AUTOSAR XML (schema 4-2-2)
package /STELLANTIS/EPT/ASWCs
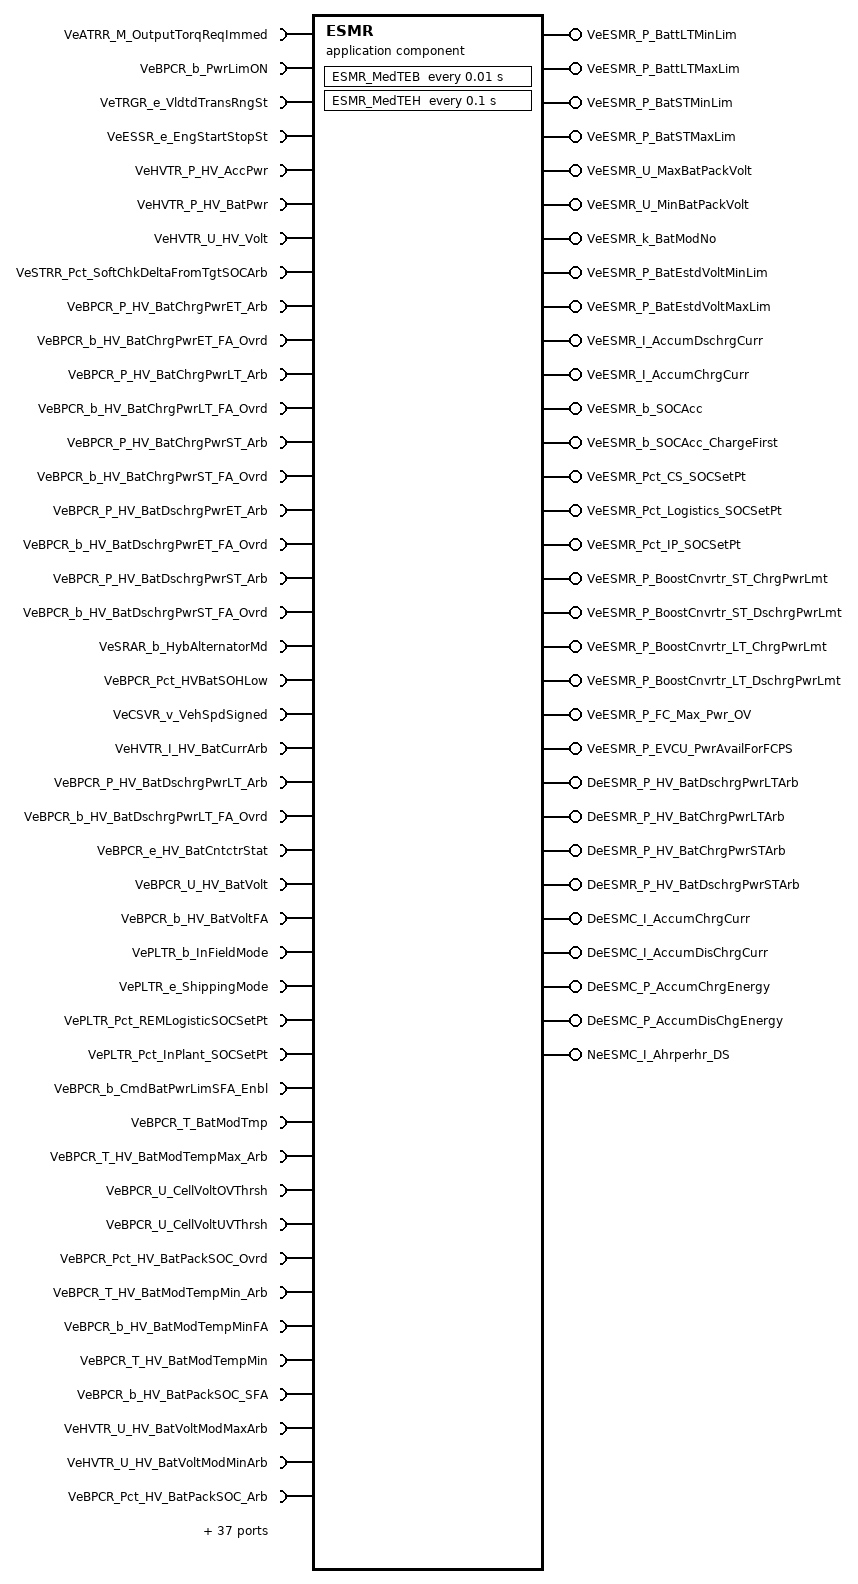
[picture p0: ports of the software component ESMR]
  application sw component type ESMR
    71 x require port:
      VeATRR_M_OutputTorqReqImmed: nonqueued-receiver-com-spec{data-element=Value, init-value=0}, required-interface=VeATRR_M_OutputTorqReqImmed
      VeBPCR_b_PwrLimON: nonqueued-receiver-com-spec{data-element=Value, init-value=0}, required-interface=VeBPCR_b_PwrLimON
      VeTRGR_e_VldtdTransRngSt: nonqueued-receiver-com-spec{data-element=Value, init-value=CeTRGR_e_NoSelectionAvailable}, required-interface=VeTRGR_e_VldtdTransRngSt
      VeESSR_e_EngStartStopSt: nonqueued-receiver-com-spec{data-element=Value, init-value=CeESSR_e_EngOff}, required-interface=VeESSR_e_EngStartStopSt
      VeHVTR_P_HV_AccPwr: nonqueued-receiver-com-spec{data-element=Value, init-value=0}, required-interface=VeHVTR_P_HV_AccPwr
      VeHVTR_P_HV_BatPwr: nonqueued-receiver-com-spec{data-element=Value, init-value=0}, required-interface=VeHVTR_P_HV_BatPwr
      VeHVTR_U_HV_Volt: nonqueued-receiver-com-spec{data-element=Value, init-value=0}, required-interface=VeHVTR_U_HV_Volt
      VeSTRR_Pct_SoftChkDeltaFromTgtSOCArb: nonqueued-receiver-com-spec{data-element=Value, init-value=0}, required-interface=VeSTRR_Pct_SoftChkDeltaFromTgtSOCArb
      VeBPCR_P_HV_BatChrgPwrET_Arb: nonqueued-receiver-com-spec{data-element=Value, init-value=0}, required-interface=VeBPCR_P_HV_BatChrgPwrET_Arb
      VeBPCR_b_HV_BatChrgPwrET_FA_Ovrd: nonqueued-receiver-com-spec{data-element=Value, init-value=0}, required-interface=VeBPCR_b_HV_BatChrgPwrET_FA_Ovrd
      VeBPCR_P_HV_BatChrgPwrLT_Arb: nonqueued-receiver-com-spec{data-element=Value, init-value=0}, required-interface=VeBPCR_P_HV_BatChrgPwrLT_Arb
      VeBPCR_b_HV_BatChrgPwrLT_FA_Ovrd: nonqueued-receiver-com-spec{data-element=Value, init-value=0}, required-interface=VeBPCR_b_HV_BatChrgPwrLT_FA_Ovrd
      VeBPCR_P_HV_BatChrgPwrST_Arb: nonqueued-receiver-com-spec{data-element=Value, init-value=0}, required-interface=VeBPCR_P_HV_BatChrgPwrST_Arb
      VeBPCR_b_HV_BatChrgPwrST_FA_Ovrd: nonqueued-receiver-com-spec{data-element=Value, init-value=0}, required-interface=VeBPCR_b_HV_BatChrgPwrST_FA_Ovrd
      VeBPCR_P_HV_BatDschrgPwrET_Arb: nonqueued-receiver-com-spec{data-element=Value, init-value=0}, required-interface=VeBPCR_P_HV_BatDschrgPwrET_Arb
      VeBPCR_b_HV_BatDschrgPwrET_FA_Ovrd: nonqueued-receiver-com-spec{data-element=Value, init-value=0}, required-interface=VeBPCR_b_HV_BatDschrgPwrET_FA_Ovrd
      VeBPCR_P_HV_BatDschrgPwrST_Arb: nonqueued-receiver-com-spec{data-element=Value, init-value=0}, required-interface=VeBPCR_P_HV_BatDschrgPwrST_Arb
      VeBPCR_b_HV_BatDschrgPwrST_FA_Ovrd: nonqueued-receiver-com-spec{data-element=Value, init-value=0}, required-interface=VeBPCR_b_HV_BatDschrgPwrST_FA_Ovrd
      VeSRAR_b_HybAlternatorMd: nonqueued-receiver-com-spec{data-element=Value, init-value=0}, required-interface=VeSRAR_b_HybAlternatorMd
      VeBPCR_Pct_HVBatSOHLow: nonqueued-receiver-com-spec{data-element=Value, init-value=0}, required-interface=VeBPCR_Pct_HVBatSOHLow
      VeCSVR_v_VehSpdSigned: nonqueued-receiver-com-spec{data-element=Value, init-value=0}, required-interface=VeCSVR_v_VehSpdSigned
      VeHVTR_I_HV_BatCurrArb: nonqueued-receiver-com-spec{data-element=Value, init-value=0}, required-interface=VeHVTR_I_HV_BatCurrArb
      VeBPCR_P_HV_BatDschrgPwrLT_Arb: nonqueued-receiver-com-spec{data-element=Value, init-value=0}, required-interface=VeBPCR_P_HV_BatDschrgPwrLT_Arb
      VeBPCR_b_HV_BatDschrgPwrLT_FA_Ovrd: nonqueued-receiver-com-spec{data-element=Value, init-value=0}, required-interface=VeBPCR_b_HV_BatDschrgPwrLT_FA_Ovrd
      VeBPCR_e_HV_BatCntctrStat: nonqueued-receiver-com-spec{data-element=Value, init-value=CeHVTR_e_Open}, required-interface=VeBPCR_e_HV_BatCntctrStat
      VeBPCR_U_HV_BatVolt: nonqueued-receiver-com-spec{data-element=Value, init-value=0}, required-interface=VeBPCR_U_HV_BatVolt
      VeBPCR_b_HV_BatVoltFA: nonqueued-receiver-com-spec{data-element=Value, init-value=0}, required-interface=VeBPCR_b_HV_BatVoltFA
      VePLTR_b_InFieldMode: nonqueued-receiver-com-spec{data-element=Value, init-value=0}, required-interface=VePLTR_b_InFieldMode
      VePLTR_e_ShippingMode: nonqueued-receiver-com-spec{data-element=Value, init-value=CePLTR_e_ShipingMode_CUST_MD}, required-interface=VePLTR_e_ShippingMode
      VePLTR_Pct_REMLogisticSOCSetPt: nonqueued-receiver-com-spec{data-element=Value, init-value=0}, required-interface=VePLTR_Pct_REMLogisticSOCSetPt
      VePLTR_Pct_InPlant_SOCSetPt: nonqueued-receiver-com-spec{data-element=Value, init-value=0}, required-interface=VePLTR_Pct_InPlant_SOCSetPt
      VeBPCR_b_CmdBatPwrLimSFA_Enbl: nonqueued-receiver-com-spec{data-element=Value, init-value=0}, required-interface=VeBPCR_b_CmdBatPwrLimSFA_Enbl
      VeBPCR_T_BatModTmp: nonqueued-receiver-com-spec{data-element=Value, init-value=0}, required-interface=VeBPCR_T_BatModTmp
      VeBPCR_T_HV_BatModTempMax_Arb: nonqueued-receiver-com-spec{data-element=Value, init-value=0}, required-interface=VeBPCR_T_HV_BatModTempMax_Arb
      VeBPCR_U_CellVoltOVThrsh: nonqueued-receiver-com-spec{data-element=Value, init-value=0}, required-interface=VeBPCR_U_CellVoltOVThrsh
      VeBPCR_U_CellVoltUVThrsh: nonqueued-receiver-com-spec{data-element=Value, init-value=0}, required-interface=VeBPCR_U_CellVoltUVThrsh
      VeBPCR_Pct_HV_BatPackSOC_Ovrd: nonqueued-receiver-com-spec{data-element=Value, init-value=0}, required-interface=VeBPCR_Pct_HV_BatPackSOC_Ovrd
      VeBPCR_T_HV_BatModTempMin_Arb: nonqueued-receiver-com-spec{data-element=Value, init-value=0}, required-interface=VeBPCR_T_HV_BatModTempMin_Arb
      VeBPCR_b_HV_BatModTempMinFA: nonqueued-receiver-com-spec{data-element=Value, init-value=0}, required-interface=VeBPCR_b_HV_BatModTempMinFA
      VeBPCR_T_HV_BatModTempMin: nonqueued-receiver-com-spec{data-element=Value, init-value=0}, required-interface=VeBPCR_T_HV_BatModTempMin
      VeBPCR_b_HV_BatPackSOC_SFA: nonqueued-receiver-com-spec{data-element=Value, init-value=0}, required-interface=VeBPCR_b_HV_BatPackSOC_SFA
      VeHVTR_U_HV_BatVoltModMaxArb: nonqueued-receiver-com-spec{data-element=Value, init-value=0}, required-interface=VeHVTR_U_HV_BatVoltModMaxArb
      VeHVTR_U_HV_BatVoltModMinArb: nonqueued-receiver-com-spec{data-element=Value, init-value=0}, required-interface=VeHVTR_U_HV_BatVoltModMinArb
      VeBPCR_Pct_HV_BatPackSOC_Arb: nonqueued-receiver-com-spec{data-element=Value, init-value=0}, required-interface=VeBPCR_Pct_HV_BatPackSOC_Arb
      VePLTR_b_InPlantAllowCharge: nonqueued-receiver-com-spec{data-element=Value, init-value=0}, required-interface=VePLTR_b_InPlantAllowCharge
      VeFCPR_U_FCPS_Volt: nonqueued-receiver-com-spec{data-element=Value, init-value=0}, required-interface=VeFCPR_U_FCPS_Volt
      VeFCPR_b_FCPS_Volt_FA: nonqueued-receiver-com-spec{data-element=Value, init-value=0}, required-interface=VeFCPR_b_FCPS_Volt_FA
      VeFCPR_U_FCPS_UpperVoltLIM: nonqueued-receiver-com-spec{data-element=Value, init-value=0}, required-interface=VeFCPR_U_FCPS_UpperVoltLIM
      VeFCPR_b_FCPS_UpperVoltLIM_FA: nonqueued-receiver-com-spec{data-element=Value, init-value=0}, required-interface=VeFCPR_b_FCPS_UpperVoltLIM_FA
      VeFCPR_U_FCPS_LowerVoltLIM: nonqueued-receiver-com-spec{data-element=Value, init-value=0}, required-interface=VeFCPR_U_FCPS_LowerVoltLIM
      VeFCPR_b_FCPS_LowerVoltLIM_FA: nonqueued-receiver-com-spec{data-element=Value, init-value=0}, required-interface=VeFCPR_b_FCPS_LowerVoltLIM_FA
      VeFCPR_P_FCPS_ShoTiDchaPwrLim: nonqueued-receiver-com-spec{data-element=Value, init-value=0}, required-interface=VeFCPR_P_FCPS_ShoTiDchaPwrLim
      VeFCPR_P_FCPS_LongTiDchaPwrLim: nonqueued-receiver-com-spec{data-element=Value, init-value=0}, required-interface=VeFCPR_P_FCPS_LongTiDchaPwrLim
      VeFCPR_P_FCPS_ActPwr: nonqueued-receiver-com-spec{data-element=Value, init-value=0}, required-interface=VeFCPR_P_FCPS_ActPwr
      VeFCPR_P_FCPS_StarUp_PwrDmnd: nonqueued-receiver-com-spec{data-element=Value, init-value=0}, required-interface=VeFCPR_P_FCPS_StarUp_PwrDmnd
      VeFCPR_b_FCPS_ShoTiDchaPwrLim_FA: nonqueued-receiver-com-spec{data-element=Value, init-value=0}, required-interface=VeFCPR_b_FCPS_ShoTiDchaPwrLim_FA
      VeFCPR_b_FCPS_LongTiDchaPwrLim_FA: nonqueued-receiver-com-spec{data-element=Value, init-value=0}, required-interface=VeFCPR_b_FCPS_LongTiDchaPwrLim_FA
      VeFCPR_b_FCPS_ActPwr_FA: nonqueued-receiver-com-spec{data-element=Value, init-value=0}, required-interface=VeFCPR_b_FCPS_ActPwr_FA
      VeFCPR_b_FCPS_StarUp_PwrDmnd_FA: nonqueued-receiver-com-spec{data-element=Value, init-value=0}, required-interface=VeFCPR_b_FCPS_StarUp_PwrDmnd_FA
      VeINVR_P_BstCnvtrChrgPwrLmt_ST: nonqueued-receiver-com-spec{data-element=Value, init-value=0}, required-interface=VeINVR_P_BstCnvtrChrgPwrLmt_ST
      VeINVR_b_BstCnvtrChrgPwrLmt_ST_FA: nonqueued-receiver-com-spec{data-element=Value, init-value=0}, required-interface=VeINVR_b_BstCnvtrChrgPwrLmt_ST_FA
      VeINVR_P_BstCnvtrDschrgPwrLmt_ST: nonqueued-receiver-com-spec{data-element=Value, init-value=0}, required-interface=VeINVR_P_BstCnvtrDschrgPwrLmt_ST
      VeINVR_b_BstCnvtrDschrgPwrLmt_ST_FA: nonqueued-receiver-com-spec{data-element=Value, init-value=0}, required-interface=VeINVR_b_BstCnvtrDschrgPwrLmt_ST_FA
      VeINVR_P_BstCnvtrChrgPwrLmt: nonqueued-receiver-com-spec{data-element=Value, init-value=0}, required-interface=VeINVR_P_BstCnvtrChrgPwrLmt
      VeINVR_b_BstCnvtrChrgPwrLmtFA: nonqueued-receiver-com-spec{data-element=Value, init-value=0}, required-interface=VeINVR_b_BstCnvtrChrgPwrLmtFA
      VeINVR_P_BstCnvtrDschrgPwrLmt: nonqueued-receiver-com-spec{data-element=Value, init-value=0}, required-interface=VeINVR_P_BstCnvtrDschrgPwrLmt
      VeINVR_b_BstCnvtrDschrgPwrLmtFA: nonqueued-receiver-com-spec{data-element=Value, init-value=0}, required-interface=VeINVR_b_BstCnvtrDschrgPwrLmtFA
      VeINVR_T_MtrA_CoolantTemp: nonqueued-receiver-com-spec{data-element=Value, init-value=0}, required-interface=VeINVR_T_MtrA_CoolantTemp
      VeINVR_b_MtrA_CoolantTempFA: nonqueued-receiver-com-spec{data-element=Value, init-value=0}, required-interface=VeINVR_b_MtrA_CoolantTempFA
      VeINVR_e_MtrA_InvrtrSt: nonqueued-receiver-com-spec{data-element=Value, init-value=CeINVR_e_NormalPowerStageOff}, required-interface=VeINVR_e_MtrA_InvrtrSt
      VeINVR_e_MtrB_InvrtrSt: nonqueued-receiver-com-spec{data-element=Value, init-value=CeINVR_e_NormalPowerStageOff}, required-interface=VeINVR_e_MtrB_InvrtrSt
    22 x provide port, all with nonqueued-sender-com-spec{data-element=Value, init-value=0}:
      VeESMR_P_BattLTMinLim: provided-interface=VeESMR_P_BattLTMinLim
      VeESMR_P_BattLTMaxLim: provided-interface=VeESMR_P_BattLTMaxLim
      VeESMR_P_BatSTMinLim: provided-interface=VeESMR_P_BatSTMinLim
      VeESMR_P_BatSTMaxLim: provided-interface=VeESMR_P_BatSTMaxLim
      VeESMR_U_MaxBatPackVolt: provided-interface=VeESMR_U_MaxBatPackVolt
      VeESMR_U_MinBatPackVolt: provided-interface=VeESMR_U_MinBatPackVolt
      VeESMR_k_BatModNo: provided-interface=VeESMR_k_BatModNo
      VeESMR_P_BatEstdVoltMinLim: provided-interface=VeESMR_P_BatEstdVoltMinLim
      VeESMR_P_BatEstdVoltMaxLim: provided-interface=VeESMR_P_BatEstdVoltMaxLim
      VeESMR_I_AccumDschrgCurr: provided-interface=VeESMR_I_AccumDschrgCurr
      VeESMR_I_AccumChrgCurr: provided-interface=VeESMR_I_AccumChrgCurr
      VeESMR_b_SOCAcc: provided-interface=VeESMR_b_SOCAcc
      VeESMR_b_SOCAcc_ChargeFirst: provided-interface=VeESMR_b_SOCAcc_ChargeFirst
      VeESMR_Pct_CS_SOCSetPt: provided-interface=VeESMR_Pct_CS_SOCSetPt
      VeESMR_Pct_Logistics_SOCSetPt: provided-interface=VeESMR_Pct_Logistics_SOCSetPt
      VeESMR_Pct_IP_SOCSetPt: provided-interface=VeESMR_Pct_IP_SOCSetPt
      VeESMR_P_BoostCnvrtr_ST_ChrgPwrLmt: provided-interface=VeESMR_P_BoostCnvrtr_ST_ChrgPwrLmt
      VeESMR_P_BoostCnvrtr_ST_DschrgPwrLmt: provided-interface=VeESMR_P_BoostCnvrtr_ST_DschrgPwrLmt
      VeESMR_P_BoostCnvrtr_LT_ChrgPwrLmt: provided-interface=VeESMR_P_BoostCnvrtr_LT_ChrgPwrLmt
      VeESMR_P_BoostCnvrtr_LT_DschrgPwrLmt: provided-interface=VeESMR_P_BoostCnvrtr_LT_DschrgPwrLmt
      VeESMR_P_FC_Max_Pwr_OV: provided-interface=VeESMR_P_FC_Max_Pwr_OV
      VeESMR_P_EVCU_PwrAvailForFCPS: provided-interface=VeESMR_P_EVCU_PwrAvailForFCPS
    9 x require port:
      DeESMR_P_HV_BatDschrgPwrLTArb_Rx: nv-require-com-spec{init-value=-100000, variable=DeESMR_P_HV_BatDschrgPwrLTArb}, required-interface=DeESMR_P_HV_BatDschrgPwrLTArb
      DeESMR_P_HV_BatChrgPwrLTArb_Rx: nv-require-com-spec{init-value=-100000, variable=DeESMR_P_HV_BatChrgPwrLTArb}, required-interface=DeESMR_P_HV_BatChrgPwrLTArb
      DeESMR_P_HV_BatChrgPwrSTArb_Rx: nv-require-com-spec{init-value=-100000, variable=DeESMR_P_HV_BatChrgPwrSTArb}, required-interface=DeESMR_P_HV_BatChrgPwrSTArb
      DeESMR_P_HV_BatDschrgPwrSTArb_Rx: nv-require-com-spec{init-value=-100000, variable=DeESMR_P_HV_BatDschrgPwrSTArb}, required-interface=DeESMR_P_HV_BatDschrgPwrSTArb
      DeESMC_I_AccumChrgCurr_Rx: nv-require-com-spec{init-value=0, variable=DeESMC_I_AccumChrgCurr}, required-interface=DeESMC_I_AccumChrgCurr
      DeESMC_I_AccumDisChrgCurr_Rx: nv-require-com-spec{init-value=0, variable=DeESMC_I_AccumDisChrgCurr}, required-interface=DeESMC_I_AccumDisChrgCurr
      DeESMC_P_AccumChrgEnergy_Rx: nv-require-com-spec{init-value=0, variable=DeESMC_P_AccumChrgEnergy}, required-interface=DeESMC_P_AccumChrgEnergy
      DeESMC_P_AccumDisChgEnergy_Rx: nv-require-com-spec{init-value=0, variable=DeESMC_P_AccumDisChgEnergy}, required-interface=DeESMC_P_AccumDisChgEnergy
      NeESMC_I_Ahrperhr_DS_Rx: nv-require-com-spec{init-value=0, variable=NeESMC_I_Ahrperhr_DS}, required-interface=NeESMC_I_Ahrperhr_DS
    9 x provide port:
      DeESMR_P_HV_BatDschrgPwrLTArb: nv-provide-com-spec{ram-block-init-value=-100000, variable=DeESMR_P_HV_BatDschrgPwrLTArb}, provided-interface=DeESMR_P_HV_BatDschrgPwrLTArb
      DeESMR_P_HV_BatChrgPwrLTArb: nv-provide-com-spec{ram-block-init-value=-100000, variable=DeESMR_P_HV_BatChrgPwrLTArb}, provided-interface=DeESMR_P_HV_BatChrgPwrLTArb
      DeESMR_P_HV_BatChrgPwrSTArb: nv-provide-com-spec{ram-block-init-value=-100000, variable=DeESMR_P_HV_BatChrgPwrSTArb}, provided-interface=DeESMR_P_HV_BatChrgPwrSTArb
      DeESMR_P_HV_BatDschrgPwrSTArb: nv-provide-com-spec{ram-block-init-value=-100000, variable=DeESMR_P_HV_BatDschrgPwrSTArb}, provided-interface=DeESMR_P_HV_BatDschrgPwrSTArb
      DeESMC_I_AccumChrgCurr: nv-provide-com-spec{ram-block-init-value=0, variable=DeESMC_I_AccumChrgCurr}, provided-interface=DeESMC_I_AccumChrgCurr
      DeESMC_I_AccumDisChrgCurr: nv-provide-com-spec{ram-block-init-value=0, variable=DeESMC_I_AccumDisChrgCurr}, provided-interface=DeESMC_I_AccumDisChrgCurr
      DeESMC_P_AccumChrgEnergy: nv-provide-com-spec{ram-block-init-value=0, variable=DeESMC_P_AccumChrgEnergy}, provided-interface=DeESMC_P_AccumChrgEnergy
      DeESMC_P_AccumDisChgEnergy: nv-provide-com-spec{ram-block-init-value=0, variable=DeESMC_P_AccumDisChgEnergy}, provided-interface=DeESMC_P_AccumDisChgEnergy
      NeESMC_I_Ahrperhr_DS: nv-provide-com-spec{ram-block-init-value=0, variable=NeESMC_I_Ahrperhr_DS}, provided-interface=NeESMC_I_Ahrperhr_DS
    require port KeESMR_k_BatModNo: parameter-require-com-spec{init-value=KeESMR_k_BatModNo_KeESMR_k_BatModNo:20, parameter=KeESMR_k_BatModNo}, required-interface=KeESMR_k_BatModNo
    behavior IB_ESMR: data-type-mapping=msADTtoIDTMapping, handle-termination-and-restart=NO-SUPPORT, included-data-type-set=data-type=TeESMR_e_ActiveLT_PwrLim
      timing event Event_MedTEB: start-on-event=ESMR_MedTEB, period=0.01
      timing event Event_MedTEH: start-on-event=ESMR_MedTEH, period=0.1
      init event Event_ESMR_ac_Init: start-on-event=ESMR_ac_Init
      init event Event_PwrOn: start-on-event=ESMR_PwrOn
      init event Event_PwrOff: start-on-event=ESMR_PwrOff
      explicit-inter-runnable-variables:
        35 x data, all with category=VALUE, sw-calibration-access=READ-ONLY:
          VeESMN_U_BatVoltModMaxArb_Init_IRV: type=Float, init-value=0
          VeESMN_U_BatVoltModMinArb_Init_IRV: type=Float, init-value=0
          VeESMR_P_BatEstdVoltMaxLim_write_IRV: type=Float, init-value=0
          VeESMR_P_BatEstdVoltMinLim_write_IRV: type=Float, init-value=0
          VeESMR_P_Total_LT_DsChrg_PwrLmtRL_IRV: type=Float, init-value=0
          VeESMR_P_Total_LT_Chrg_PwrLmtRL_IRV: type=Float, init-value=0
          VeESMR_P_Total_ST_DsChrg_PwrLmtRL_IRV: type=Float, init-value=0
          VeESMC_e_DschrgPwrLimST_ID_A_IRV: type=TeESMR_e_ActiveST_PwrLim, init-value=CeESMR_e_MinChrgLimST
          VeESMR_P_Total_ST_Chrg_PwrLmtRL_IRV: type=Float, init-value=0, variation-point={short-label=vpVeESMR_P_Total_ST_Chrg_PwrLmtRL_IRV, sw-syscond=1}
          VeESMC_e_ChrgPwrLimST_ID_A_IRV: type=TeESMR_e_ActiveST_PwrLim, init-value=CeESMR_e_MinChrgLimST
          VeESMN_e_EngStartStopSt_IRV: type=TeESSR_e_EngStartStopSt, init-value=CeESSR_e_EngOff
          VeESMN_e_HVBatCntctrStat_IRV: type=TeHVTR_e_HV_BatCntctrStat, init-value=CeHVTR_e_Open
          VeESMR_U_FCPS_Volt_IRV: type=Float, init-value=0
          VeESMR_b_FCPS_Volt_FA_IRV: type=Boolean, init-value=0
          VeESMR_U_FCPS_UpperVoltLIM_IRV: type=Float, init-value=0
          VeESMR_b_FCPS_Upper_Voltage_LIM_FA_IRV: type=Boolean, init-value=0
          VeESMR_U_FCPS_LowerVoltLIM_IRV: type=Float, init-value=0
          VeESMR_b_FCPS_Lower_Voltage_LIM_FA_IRV: type=Boolean, init-value=0
          VeESMC_P_ChrgPwrLimST_RL_IRV: type=Float, init-value=0
          VeESMR_P_FCPS_Gen_Pwr_IRV: type=Float, init-value=0
          HybAlternatorMd_IRV: type=Boolean, init-value=0
          AhrperhrNorm_write_IRV: type=Float, init-value=0
          VeESMR_P_BattLTMinLim1_IRV: type=Float, init-value=0
          VeESMR_P_BattLTMaxLim1_IRV: type=Float, init-value=0
          VeESMR_P_BatSTMinLim1_IRV: type=Float, init-value=0
          VeESMR_P_BatSTMaxLim1_IRV: type=Float, init-value=0
          VeESMR_U_MaxBatPackVolt_IRV: type=Float, init-value=0
          VeESMR_U_MinBatPackVolt_IRV: type=Float, init-value=0
          VeESMR_k_BatModNo_IRV: type=Float, init-value=0
          VeESMR_b_SOCAcc_IRV: type=Boolean, init-value=0
          VeESMR_b_SOCAcc_ChargeFirst_IRV: type=Boolean, init-value=0
          BatLT_MaxLimInit1_IRV: type=Float, init-value=0
          BatLT_MinLimInit1_IRV: type=Float, init-value=0
          BatST_MinLimInit1_IRV: type=Float, init-value=0
          BatST_MaxLimInit1_IRV: type=Float, init-value=0
      5 x runnable:
        ESMR_ac_Init
          written-local-variables:
            32 x access:
              WV_BatLT_MaxLimInit1_IRV: accessed-variable=BatLT_MaxLimInit1_IRV
              WV_BatLT_MinLimInit1_IRV: accessed-variable=BatLT_MinLimInit1_IRV
              WV_BatST_MaxLimInit1_IRV: accessed-variable=BatST_MaxLimInit1_IRV
              WV_BatST_MinLimInit1_IRV: accessed-variable=BatST_MinLimInit1_IRV
              WV_VeESMN_U_BatVoltModMaxArb_Init_IRV: accessed-variable=VeESMN_U_BatVoltModMaxArb_Init_IRV
              WV_VeESMN_U_BatVoltModMinArb_Init_IRV: accessed-variable=VeESMN_U_BatVoltModMinArb_Init_IRV
              WV_VeESMR_U_MaxBatPackVolt_IRV: accessed-variable=VeESMR_U_MaxBatPackVolt_IRV
              WV_VeESMR_U_MinBatPackVolt_IRV: accessed-variable=VeESMR_U_MinBatPackVolt_IRV
              WV_VeESMR_b_SOCAcc_IRV: accessed-variable=VeESMR_b_SOCAcc_IRV
              WV_VeESMR_b_SOCAcc_ChargeFirst_IRV: accessed-variable=VeESMR_b_SOCAcc_ChargeFirst_IRV
              WV_VeESMR_k_BatModNo_IRV: accessed-variable=VeESMR_k_BatModNo_IRV
              WV_HybAlternatorMd_IRV: accessed-variable=HybAlternatorMd_IRV
              WV_VeESMC_P_ChrgPwrLimST_RL_IRV: accessed-variable=VeESMC_P_ChrgPwrLimST_RL_IRV
              WV_VeESMC_e_ChrgPwrLimST_ID_A_IRV: accessed-variable=VeESMC_e_ChrgPwrLimST_ID_A_IRV
              WV_VeESMC_e_DschrgPwrLimST_ID_A_IRV: accessed-variable=VeESMC_e_DschrgPwrLimST_ID_A_IRV
              WV_VeESMN_e_EngStartStopSt_IRV: accessed-variable=VeESMN_e_EngStartStopSt_IRV
              WV_VeESMN_e_HVBatCntctrStat_IRV: accessed-variable=VeESMN_e_HVBatCntctrStat_IRV
              WV_VeESMR_P_FCPS_Gen_Pwr_IRV: accessed-variable=VeESMR_P_FCPS_Gen_Pwr_IRV
              WV_VeESMR_P_Total_LT_Chrg_PwrLmtRL_IRV: accessed-variable=VeESMR_P_Total_LT_Chrg_PwrLmtRL_IRV
              WV_VeESMR_P_Total_LT_DsChrg_PwrLmtRL_IRV: accessed-variable=VeESMR_P_Total_LT_DsChrg_PwrLmtRL_IRV
              WV_VeESMR_P_Total_ST_Chrg_PwrLmtRL_IRV: accessed-variable=VeESMR_P_Total_ST_Chrg_PwrLmtRL_IRV, variation-point={short-label=vpWV_VeESMR_P_Total_ST_Chrg_PwrLmtRL_IRV, sw-syscond=1}
              WV_VeESMR_P_Total_ST_DsChrg_PwrLmtRL_IRV: accessed-variable=VeESMR_P_Total_ST_DsChrg_PwrLmtRL_IRV
              WV_VeESMR_U_FCPS_LowerVoltLIM_IRV: accessed-variable=VeESMR_U_FCPS_LowerVoltLIM_IRV
              WV_VeESMR_U_FCPS_UpperVoltLIM_IRV: accessed-variable=VeESMR_U_FCPS_UpperVoltLIM_IRV
              WV_VeESMR_U_FCPS_Volt_IRV: accessed-variable=VeESMR_U_FCPS_Volt_IRV
              WV_VeESMR_b_FCPS_Lower_Voltage_LIM_FA_IRV: accessed-variable=VeESMR_b_FCPS_Lower_Voltage_LIM_FA_IRV
              WV_VeESMR_b_FCPS_Upper_Voltage_LIM_FA_IRV: accessed-variable=VeESMR_b_FCPS_Upper_Voltage_LIM_FA_IRV
              WV_VeESMR_b_FCPS_Volt_FA_IRV: accessed-variable=VeESMR_b_FCPS_Volt_FA_IRV
              WV_VeESMR_P_BatSTMaxLim1_IRV: accessed-variable=VeESMR_P_BatSTMaxLim1_IRV
              WV_VeESMR_P_BatSTMinLim1_IRV: accessed-variable=VeESMR_P_BatSTMinLim1_IRV
              WV_VeESMR_P_BattLTMaxLim1_IRV: accessed-variable=VeESMR_P_BattLTMaxLim1_IRV
              WV_VeESMR_P_BattLTMinLim1_IRV: accessed-variable=VeESMR_P_BattLTMinLim1_IRV
        ESMR_PwrOn
          data-receive-point-by-arguments:
            11 x access:
              IN_DeESMC_I_AccumChrgCurr_Rx_DeESMC_I_AccumChrgCurr: accessed-variable=DeESMC_I_AccumChrgCurr_Rx.DeESMC_I_AccumChrgCurr
              IN_DeESMC_I_AccumDisChrgCurr_Rx_DeESMC_I_AccumDisChrgCurr: accessed-variable=DeESMC_I_AccumDisChrgCurr_Rx.DeESMC_I_AccumDisChrgCurr
              IN_DeESMC_P_AccumChrgEnergy_Rx_DeESMC_P_AccumChrgEnergy: accessed-variable=DeESMC_P_AccumChrgEnergy_Rx.DeESMC_P_AccumChrgEnergy
              IN_DeESMC_P_AccumDisChgEnergy_Rx_DeESMC_P_AccumDisChgEnergy: accessed-variable=DeESMC_P_AccumDisChgEnergy_Rx.DeESMC_P_AccumDisChgEnergy
              IN_DeESMR_P_HV_BatChrgPwrLTArb_Rx_DeESMR_P_HV_BatChrgPwrLTArb: accessed-variable=DeESMR_P_HV_BatChrgPwrLTArb_Rx.DeESMR_P_HV_BatChrgPwrLTArb
              IN_DeESMR_P_HV_BatChrgPwrSTArb_Rx_DeESMR_P_HV_BatChrgPwrSTArb: accessed-variable=DeESMR_P_HV_BatChrgPwrSTArb_Rx.DeESMR_P_HV_BatChrgPwrSTArb
              IN_DeESMR_P_HV_BatDschrgPwrLTArb_Rx_DeESMR_P_HV_BatDschrgPwrLTArb: accessed-variable=DeESMR_P_HV_BatDschrgPwrLTArb_Rx.DeESMR_P_HV_BatDschrgPwrLTArb
              IN_DeESMR_P_HV_BatDschrgPwrSTArb_Rx_DeESMR_P_HV_BatDschrgPwrSTArb: accessed-variable=DeESMR_P_HV_BatDschrgPwrSTArb_Rx.DeESMR_P_HV_BatDschrgPwrSTArb
              IN_NeESMC_I_Ahrperhr_DS_Rx_NeESMC_I_Ahrperhr_DS: accessed-variable=NeESMC_I_Ahrperhr_DS_Rx.NeESMC_I_Ahrperhr_DS
              IN_VeHVTR_U_HV_BatVoltModMaxArb_Value: accessed-variable=VeHVTR_U_HV_BatVoltModMaxArb.Value
              IN_VeHVTR_U_HV_BatVoltModMinArb_Value: accessed-variable=VeHVTR_U_HV_BatVoltModMinArb.Value
          data-send-points:
            22 x access:
              OUT_VeESMR_P_BattLTMinLim_Value: accessed-variable=VeESMR_P_BattLTMinLim.Value
              OUT_VeESMR_P_BattLTMaxLim_Value: accessed-variable=VeESMR_P_BattLTMaxLim.Value
              OUT_VeESMR_P_BatSTMinLim_Value: accessed-variable=VeESMR_P_BatSTMinLim.Value
              OUT_VeESMR_P_BatSTMaxLim_Value: accessed-variable=VeESMR_P_BatSTMaxLim.Value
              OUT_VeESMR_P_BatEstdVoltMinLim_Value: accessed-variable=VeESMR_P_BatEstdVoltMinLim.Value
              OUT_VeESMR_P_BatEstdVoltMaxLim_Value: accessed-variable=VeESMR_P_BatEstdVoltMaxLim.Value
              OUT_VeESMR_U_MaxBatPackVolt_Value: accessed-variable=VeESMR_U_MaxBatPackVolt.Value
              OUT_VeESMR_U_MinBatPackVolt_Value: accessed-variable=VeESMR_U_MinBatPackVolt.Value
              OUT_VeESMR_k_BatModNo_Value: accessed-variable=VeESMR_k_BatModNo.Value
              OUT_VeESMR_I_AccumDschrgCurr_Value: accessed-variable=VeESMR_I_AccumDschrgCurr.Value
              OUT_VeESMR_I_AccumChrgCurr_Value: accessed-variable=VeESMR_I_AccumChrgCurr.Value
              OUT_VeESMR_b_SOCAcc_Value: accessed-variable=VeESMR_b_SOCAcc.Value
              OUT_VeESMR_b_SOCAcc_ChargeFirst_Value: accessed-variable=VeESMR_b_SOCAcc_ChargeFirst.Value
              OUT_VeESMR_Pct_CS_SOCSetPt_Value: accessed-variable=VeESMR_Pct_CS_SOCSetPt.Value
              OUT_VeESMR_Pct_Logistics_SOCSetPt_Value: accessed-variable=VeESMR_Pct_Logistics_SOCSetPt.Value
              OUT_VeESMR_Pct_IP_SOCSetPt_Value: accessed-variable=VeESMR_Pct_IP_SOCSetPt.Value
              OUT_VeESMR_P_BoostCnvrtr_ST_ChrgPwrLmt_Value: accessed-variable=VeESMR_P_BoostCnvrtr_ST_ChrgPwrLmt.Value
              OUT_VeESMR_P_BoostCnvrtr_ST_DschrgPwrLmt_Value: accessed-variable=VeESMR_P_BoostCnvrtr_ST_DschrgPwrLmt.Value
              OUT_VeESMR_P_BoostCnvrtr_LT_ChrgPwrLmt_Value: accessed-variable=VeESMR_P_BoostCnvrtr_LT_ChrgPwrLmt.Value
              OUT_VeESMR_P_BoostCnvrtr_LT_DschrgPwrLmt_Value: accessed-variable=VeESMR_P_BoostCnvrtr_LT_DschrgPwrLmt.Value
              OUT_VeESMR_P_FC_Max_Pwr_OV_Value: accessed-variable=VeESMR_P_FC_Max_Pwr_OV.Value
              OUT_VeESMR_P_EVCU_PwrAvailForFCPS_Value: accessed-variable=VeESMR_P_EVCU_PwrAvailForFCPS.Value
          parameter access CALPRM_KeESMR_k_BatModNo_KeESMR_k_BatModNo: accessed-parameter=KeESMR_k_BatModNo.KeESMR_k_BatModNo
          written-local-variables:
            14 x access:
              WV_AhrperhrNorm_write_IRV: accessed-variable=AhrperhrNorm_write_IRV
              WV_BatLT_MaxLimInit1_IRV: accessed-variable=BatLT_MaxLimInit1_IRV
              WV_BatLT_MinLimInit1_IRV: accessed-variable=BatLT_MinLimInit1_IRV
              WV_BatST_MaxLimInit1_IRV: accessed-variable=BatST_MaxLimInit1_IRV
              WV_BatST_MinLimInit1_IRV: accessed-variable=BatST_MinLimInit1_IRV
              WV_VeESMN_U_BatVoltModMaxArb_Init_IRV: accessed-variable=VeESMN_U_BatVoltModMaxArb_Init_IRV
              WV_VeESMN_U_BatVoltModMinArb_Init_IRV: accessed-variable=VeESMN_U_BatVoltModMinArb_Init_IRV
              WV_VeESMR_P_BatEstdVoltMaxLim_write_IRV: accessed-variable=VeESMR_P_BatEstdVoltMaxLim_write_IRV
              WV_VeESMR_P_BatEstdVoltMinLim_write_IRV: accessed-variable=VeESMR_P_BatEstdVoltMinLim_write_IRV
              WV_VeESMR_U_MaxBatPackVolt_IRV: accessed-variable=VeESMR_U_MaxBatPackVolt_IRV
              WV_VeESMR_U_MinBatPackVolt_IRV: accessed-variable=VeESMR_U_MinBatPackVolt_IRV
              WV_VeESMR_b_SOCAcc_IRV: accessed-variable=VeESMR_b_SOCAcc_IRV
              WV_VeESMR_b_SOCAcc_ChargeFirst_IRV: accessed-variable=VeESMR_b_SOCAcc_ChargeFirst_IRV
              WV_VeESMR_k_BatModNo_IRV: accessed-variable=VeESMR_k_BatModNo_IRV
        ESMR_MedTEB
          data-receive-point-by-arguments:
            7 x access:
              IN_VeBPCR_T_BatModTmp_Value: accessed-variable=VeBPCR_T_BatModTmp.Value
              IN_VeBPCR_U_CellVoltOVThrsh_Value: accessed-variable=VeBPCR_U_CellVoltOVThrsh.Value
              IN_VeBPCR_U_CellVoltUVThrsh_Value: accessed-variable=VeBPCR_U_CellVoltUVThrsh.Value
              IN_VeBPCR_b_PwrLimON_Value: accessed-variable=VeBPCR_b_PwrLimON.Value
              IN_VeHVTR_P_HV_AccPwr_Value: accessed-variable=VeHVTR_P_HV_AccPwr.Value
              IN_VeHVTR_U_HV_BatVoltModMaxArb_Value: accessed-variable=VeHVTR_U_HV_BatVoltModMaxArb.Value
              IN_VeHVTR_U_HV_BatVoltModMinArb_Value: accessed-variable=VeHVTR_U_HV_BatVoltModMinArb.Value
          data-send-points:
            access OUT_VeESMR_P_FC_Max_Pwr_OV_Value: accessed-variable=VeESMR_P_FC_Max_Pwr_OV.Value
          read-local-variables:
            13 x access:
              RV_HybAlternatorMd_IRV: accessed-variable=HybAlternatorMd_IRV
              RV_VeESMC_e_ChrgPwrLimST_ID_A_IRV: accessed-variable=VeESMC_e_ChrgPwrLimST_ID_A_IRV
              RV_VeESMC_e_DschrgPwrLimST_ID_A_IRV: accessed-variable=VeESMC_e_DschrgPwrLimST_ID_A_IRV
              RV_VeESMN_U_BatVoltModMaxArb_Init_IRV: accessed-variable=VeESMN_U_BatVoltModMaxArb_Init_IRV
              RV_VeESMN_U_BatVoltModMinArb_Init_IRV: accessed-variable=VeESMN_U_BatVoltModMinArb_Init_IRV
              RV_VeESMN_e_EngStartStopSt_IRV: accessed-variable=VeESMN_e_EngStartStopSt_IRV
              RV_VeESMN_e_HVBatCntctrStat_IRV: accessed-variable=VeESMN_e_HVBatCntctrStat_IRV
              RV_VeESMR_P_BatEstdVoltMaxLim_write_IRV: accessed-variable=VeESMR_P_BatEstdVoltMaxLim_write_IRV
              RV_VeESMR_P_BatEstdVoltMinLim_write_IRV: accessed-variable=VeESMR_P_BatEstdVoltMinLim_write_IRV
              RV_VeESMR_P_Total_LT_Chrg_PwrLmtRL_IRV: accessed-variable=VeESMR_P_Total_LT_Chrg_PwrLmtRL_IRV
              RV_VeESMR_P_Total_LT_DsChrg_PwrLmtRL_IRV: accessed-variable=VeESMR_P_Total_LT_DsChrg_PwrLmtRL_IRV
              RV_VeESMR_P_Total_ST_Chrg_PwrLmtRL_IRV: accessed-variable=VeESMR_P_Total_ST_Chrg_PwrLmtRL_IRV, variation-point={short-label=vpRV_VeESMR_P_Total_ST_Chrg_PwrLmtRL_IRV, sw-syscond=1}
              RV_VeESMR_P_Total_ST_DsChrg_PwrLmtRL_IRV: accessed-variable=VeESMR_P_Total_ST_DsChrg_PwrLmtRL_IRV
          written-local-variables:
            4 x access:
              WV_VeESMR_P_BatSTMaxLim1_IRV: accessed-variable=VeESMR_P_BatSTMaxLim1_IRV
              WV_VeESMR_P_BatSTMinLim1_IRV: accessed-variable=VeESMR_P_BatSTMinLim1_IRV
              WV_VeESMR_P_BattLTMaxLim1_IRV: accessed-variable=VeESMR_P_BattLTMaxLim1_IRV
              WV_VeESMR_P_BattLTMinLim1_IRV: accessed-variable=VeESMR_P_BattLTMinLim1_IRV
        ESMR_MedTEH
          data-receive-point-by-arguments:
            65 x access:
              IN_VeATRR_M_OutputTorqReqImmed_Value: accessed-variable=VeATRR_M_OutputTorqReqImmed.Value
              IN_VeBPCR_P_HV_BatChrgPwrET_Arb_Value: accessed-variable=VeBPCR_P_HV_BatChrgPwrET_Arb.Value
              IN_VeBPCR_P_HV_BatChrgPwrLT_Arb_Value: accessed-variable=VeBPCR_P_HV_BatChrgPwrLT_Arb.Value
              IN_VeBPCR_P_HV_BatChrgPwrST_Arb_Value: accessed-variable=VeBPCR_P_HV_BatChrgPwrST_Arb.Value
              IN_VeBPCR_P_HV_BatDschrgPwrET_Arb_Value: accessed-variable=VeBPCR_P_HV_BatDschrgPwrET_Arb.Value
              IN_VeBPCR_P_HV_BatDschrgPwrLT_Arb_Value: accessed-variable=VeBPCR_P_HV_BatDschrgPwrLT_Arb.Value
              IN_VeBPCR_P_HV_BatDschrgPwrST_Arb_Value: accessed-variable=VeBPCR_P_HV_BatDschrgPwrST_Arb.Value
              IN_VeBPCR_Pct_HVBatSOHLow_Value: accessed-variable=VeBPCR_Pct_HVBatSOHLow.Value
              IN_VeBPCR_Pct_HV_BatPackSOC_Arb_Value: accessed-variable=VeBPCR_Pct_HV_BatPackSOC_Arb.Value
              IN_VeBPCR_Pct_HV_BatPackSOC_Ovrd_Value: accessed-variable=VeBPCR_Pct_HV_BatPackSOC_Ovrd.Value
              IN_VeBPCR_T_HV_BatModTempMax_Arb_Value: accessed-variable=VeBPCR_T_HV_BatModTempMax_Arb.Value
              IN_VeBPCR_T_HV_BatModTempMin_Value: accessed-variable=VeBPCR_T_HV_BatModTempMin.Value
              IN_VeBPCR_T_HV_BatModTempMin_Arb_Value: accessed-variable=VeBPCR_T_HV_BatModTempMin_Arb.Value
              IN_VeBPCR_U_HV_BatVolt_Value: accessed-variable=VeBPCR_U_HV_BatVolt.Value
              IN_VeBPCR_b_CmdBatPwrLimSFA_Enbl_Value: accessed-variable=VeBPCR_b_CmdBatPwrLimSFA_Enbl.Value
              IN_VeBPCR_b_HV_BatChrgPwrET_FA_Ovrd_Value: accessed-variable=VeBPCR_b_HV_BatChrgPwrET_FA_Ovrd.Value
              IN_VeBPCR_b_HV_BatChrgPwrLT_FA_Ovrd_Value: accessed-variable=VeBPCR_b_HV_BatChrgPwrLT_FA_Ovrd.Value
              IN_VeBPCR_b_HV_BatChrgPwrST_FA_Ovrd_Value: accessed-variable=VeBPCR_b_HV_BatChrgPwrST_FA_Ovrd.Value
              IN_VeBPCR_b_HV_BatDschrgPwrET_FA_Ovrd_Value: accessed-variable=VeBPCR_b_HV_BatDschrgPwrET_FA_Ovrd.Value
              IN_VeBPCR_b_HV_BatDschrgPwrLT_FA_Ovrd_Value: accessed-variable=VeBPCR_b_HV_BatDschrgPwrLT_FA_Ovrd.Value
              IN_VeBPCR_b_HV_BatDschrgPwrST_FA_Ovrd_Value: accessed-variable=VeBPCR_b_HV_BatDschrgPwrST_FA_Ovrd.Value
              IN_VeBPCR_b_HV_BatModTempMinFA_Value: accessed-variable=VeBPCR_b_HV_BatModTempMinFA.Value
              IN_VeBPCR_b_HV_BatPackSOC_SFA_Value: accessed-variable=VeBPCR_b_HV_BatPackSOC_SFA.Value
              IN_VeBPCR_b_HV_BatVoltFA_Value: accessed-variable=VeBPCR_b_HV_BatVoltFA.Value
              IN_VeBPCR_b_PwrLimON_Value: accessed-variable=VeBPCR_b_PwrLimON.Value
              IN_VeBPCR_e_HV_BatCntctrStat_Value: accessed-variable=VeBPCR_e_HV_BatCntctrStat.Value
              IN_VeCSVR_v_VehSpdSigned_Value: accessed-variable=VeCSVR_v_VehSpdSigned.Value
              IN_VeESSR_e_EngStartStopSt_Value: accessed-variable=VeESSR_e_EngStartStopSt.Value
              IN_VeFCPR_P_FCPS_ActPwr_Value: accessed-variable=VeFCPR_P_FCPS_ActPwr.Value
              IN_VeFCPR_P_FCPS_LongTiDchaPwrLim_Value: accessed-variable=VeFCPR_P_FCPS_LongTiDchaPwrLim.Value
              IN_VeFCPR_P_FCPS_ShoTiDchaPwrLim_Value: accessed-variable=VeFCPR_P_FCPS_ShoTiDchaPwrLim.Value
              IN_VeFCPR_P_FCPS_StarUp_PwrDmnd_Value: accessed-variable=VeFCPR_P_FCPS_StarUp_PwrDmnd.Value
              IN_VeFCPR_U_FCPS_LowerVoltLIM_Value: accessed-variable=VeFCPR_U_FCPS_LowerVoltLIM.Value
              IN_VeFCPR_U_FCPS_UpperVoltLIM_Value: accessed-variable=VeFCPR_U_FCPS_UpperVoltLIM.Value
              IN_VeFCPR_U_FCPS_Volt_Value: accessed-variable=VeFCPR_U_FCPS_Volt.Value
              IN_VeFCPR_b_FCPS_ActPwr_FA_Value: accessed-variable=VeFCPR_b_FCPS_ActPwr_FA.Value
              IN_VeFCPR_b_FCPS_LongTiDchaPwrLim_FA_Value: accessed-variable=VeFCPR_b_FCPS_LongTiDchaPwrLim_FA.Value
              IN_VeFCPR_b_FCPS_LowerVoltLIM_FA_Value: accessed-variable=VeFCPR_b_FCPS_LowerVoltLIM_FA.Value
              IN_VeFCPR_b_FCPS_ShoTiDchaPwrLim_FA_Value: accessed-variable=VeFCPR_b_FCPS_ShoTiDchaPwrLim_FA.Value
              IN_VeFCPR_b_FCPS_StarUp_PwrDmnd_FA_Value: accessed-variable=VeFCPR_b_FCPS_StarUp_PwrDmnd_FA.Value
              IN_VeFCPR_b_FCPS_UpperVoltLIM_FA_Value: accessed-variable=VeFCPR_b_FCPS_UpperVoltLIM_FA.Value
              IN_VeFCPR_b_FCPS_Volt_FA_Value: accessed-variable=VeFCPR_b_FCPS_Volt_FA.Value
              IN_VeHVTR_I_HV_BatCurrArb_Value: accessed-variable=VeHVTR_I_HV_BatCurrArb.Value
              IN_VeHVTR_P_HV_BatPwr_Value: accessed-variable=VeHVTR_P_HV_BatPwr.Value
              IN_VeHVTR_U_HV_Volt_Value: accessed-variable=VeHVTR_U_HV_Volt.Value
              IN_VeINVR_P_BstCnvtrChrgPwrLmt_Value: accessed-variable=VeINVR_P_BstCnvtrChrgPwrLmt.Value
              IN_VeINVR_P_BstCnvtrChrgPwrLmt_ST_Value: accessed-variable=VeINVR_P_BstCnvtrChrgPwrLmt_ST.Value
              IN_VeINVR_P_BstCnvtrDschrgPwrLmt_Value: accessed-variable=VeINVR_P_BstCnvtrDschrgPwrLmt.Value
              IN_VeINVR_P_BstCnvtrDschrgPwrLmt_ST_Value: accessed-variable=VeINVR_P_BstCnvtrDschrgPwrLmt_ST.Value
              IN_VeINVR_T_MtrA_CoolantTemp_Value: accessed-variable=VeINVR_T_MtrA_CoolantTemp.Value
              IN_VeINVR_b_BstCnvtrChrgPwrLmtFA_Value: accessed-variable=VeINVR_b_BstCnvtrChrgPwrLmtFA.Value
              IN_VeINVR_b_BstCnvtrChrgPwrLmt_ST_FA_Value: accessed-variable=VeINVR_b_BstCnvtrChrgPwrLmt_ST_FA.Value
              IN_VeINVR_b_BstCnvtrDschrgPwrLmtFA_Value: accessed-variable=VeINVR_b_BstCnvtrDschrgPwrLmtFA.Value
              IN_VeINVR_b_BstCnvtrDschrgPwrLmt_ST_FA_Value: accessed-variable=VeINVR_b_BstCnvtrDschrgPwrLmt_ST_FA.Value
              IN_VeINVR_b_MtrA_CoolantTempFA_Value: accessed-variable=VeINVR_b_MtrA_CoolantTempFA.Value
              IN_VeINVR_e_MtrA_InvrtrSt_Value: accessed-variable=VeINVR_e_MtrA_InvrtrSt.Value
              IN_VeINVR_e_MtrB_InvrtrSt_Value: accessed-variable=VeINVR_e_MtrB_InvrtrSt.Value
              IN_VePLTR_Pct_InPlant_SOCSetPt_Value: accessed-variable=VePLTR_Pct_InPlant_SOCSetPt.Value
              IN_VePLTR_Pct_REMLogisticSOCSetPt_Value: accessed-variable=VePLTR_Pct_REMLogisticSOCSetPt.Value
              IN_VePLTR_b_InFieldMode_Value: accessed-variable=VePLTR_b_InFieldMode.Value
              IN_VePLTR_b_InPlantAllowCharge_Value: accessed-variable=VePLTR_b_InPlantAllowCharge.Value
              IN_VePLTR_e_ShippingMode_Value: accessed-variable=VePLTR_e_ShippingMode.Value
              IN_VeSRAR_b_HybAlternatorMd_Value: accessed-variable=VeSRAR_b_HybAlternatorMd.Value
              IN_VeSTRR_Pct_SoftChkDeltaFromTgtSOCArb_Value: accessed-variable=VeSTRR_Pct_SoftChkDeltaFromTgtSOCArb.Value
              IN_VeTRGR_e_VldtdTransRngSt_Value: accessed-variable=VeTRGR_e_VldtdTransRngSt.Value
          data-send-points:
            21 x access:
              OUT_VeESMR_Pct_Logistics_SOCSetPt_Value: accessed-variable=VeESMR_Pct_Logistics_SOCSetPt.Value
              OUT_VeESMR_Pct_IP_SOCSetPt_Value: accessed-variable=VeESMR_Pct_IP_SOCSetPt.Value
              OUT_VeESMR_P_BattLTMinLim_Value: accessed-variable=VeESMR_P_BattLTMinLim.Value
              OUT_VeESMR_P_BattLTMaxLim_Value: accessed-variable=VeESMR_P_BattLTMaxLim.Value
              OUT_VeESMR_P_BatSTMinLim_Value: accessed-variable=VeESMR_P_BatSTMinLim.Value
              OUT_VeESMR_P_BatSTMaxLim_Value: accessed-variable=VeESMR_P_BatSTMaxLim.Value
              OUT_VeESMR_P_BatEstdVoltMinLim_Value: accessed-variable=VeESMR_P_BatEstdVoltMinLim.Value
              OUT_VeESMR_P_BatEstdVoltMaxLim_Value: accessed-variable=VeESMR_P_BatEstdVoltMaxLim.Value
              OUT_VeESMR_U_MaxBatPackVolt_Value: accessed-variable=VeESMR_U_MaxBatPackVolt.Value
              OUT_VeESMR_U_MinBatPackVolt_Value: accessed-variable=VeESMR_U_MinBatPackVolt.Value
              OUT_VeESMR_k_BatModNo_Value: accessed-variable=VeESMR_k_BatModNo.Value
              OUT_VeESMR_I_AccumDschrgCurr_Value: accessed-variable=VeESMR_I_AccumDschrgCurr.Value
              OUT_VeESMR_I_AccumChrgCurr_Value: accessed-variable=VeESMR_I_AccumChrgCurr.Value
              OUT_VeESMR_b_SOCAcc_Value: accessed-variable=VeESMR_b_SOCAcc.Value
              OUT_VeESMR_b_SOCAcc_ChargeFirst_Value: accessed-variable=VeESMR_b_SOCAcc_ChargeFirst.Value
              OUT_VeESMR_Pct_CS_SOCSetPt_Value: accessed-variable=VeESMR_Pct_CS_SOCSetPt.Value
              OUT_VeESMR_P_BoostCnvrtr_ST_ChrgPwrLmt_Value: accessed-variable=VeESMR_P_BoostCnvrtr_ST_ChrgPwrLmt.Value
              OUT_VeESMR_P_BoostCnvrtr_ST_DschrgPwrLmt_Value: accessed-variable=VeESMR_P_BoostCnvrtr_ST_DschrgPwrLmt.Value
              OUT_VeESMR_P_BoostCnvrtr_LT_ChrgPwrLmt_Value: accessed-variable=VeESMR_P_BoostCnvrtr_LT_ChrgPwrLmt.Value
              OUT_VeESMR_P_BoostCnvrtr_LT_DschrgPwrLmt_Value: accessed-variable=VeESMR_P_BoostCnvrtr_LT_DschrgPwrLmt.Value
              OUT_VeESMR_P_EVCU_PwrAvailForFCPS_Value: accessed-variable=VeESMR_P_EVCU_PwrAvailForFCPS.Value
          read-local-variables:
            14 x access:
              RV_AhrperhrNorm_write_IRV: accessed-variable=AhrperhrNorm_write_IRV
              RV_BatLT_MaxLimInit1_IRV: accessed-variable=BatLT_MaxLimInit1_IRV
              RV_BatLT_MinLimInit1_IRV: accessed-variable=BatLT_MinLimInit1_IRV
              RV_BatST_MaxLimInit1_IRV: accessed-variable=BatST_MaxLimInit1_IRV
              RV_BatST_MinLimInit1_IRV: accessed-variable=BatST_MinLimInit1_IRV
              RV_VeESMR_P_BatSTMaxLim1_IRV: accessed-variable=VeESMR_P_BatSTMaxLim1_IRV
              RV_VeESMR_P_BatSTMinLim1_IRV: accessed-variable=VeESMR_P_BatSTMinLim1_IRV
              RV_VeESMR_P_BattLTMaxLim1_IRV: accessed-variable=VeESMR_P_BattLTMaxLim1_IRV
              RV_VeESMR_P_BattLTMinLim1_IRV: accessed-variable=VeESMR_P_BattLTMinLim1_IRV
              RV_VeESMR_U_MaxBatPackVolt_IRV: accessed-variable=VeESMR_U_MaxBatPackVolt_IRV
              RV_VeESMR_U_MinBatPackVolt_IRV: accessed-variable=VeESMR_U_MinBatPackVolt_IRV
              RV_VeESMR_b_SOCAcc_ChargeFirst_IRV: accessed-variable=VeESMR_b_SOCAcc_ChargeFirst_IRV
              RV_VeESMR_b_SOCAcc_IRV: accessed-variable=VeESMR_b_SOCAcc_IRV
              RV_VeESMR_k_BatModNo_IRV: accessed-variable=VeESMR_k_BatModNo_IRV
          written-local-variables:
            20 x access:
              WV_AhrperhrNorm_write_IRV: accessed-variable=AhrperhrNorm_write_IRV
              WV_HybAlternatorMd_IRV: accessed-variable=HybAlternatorMd_IRV
              WV_VeESMC_P_ChrgPwrLimST_RL_IRV: accessed-variable=VeESMC_P_ChrgPwrLimST_RL_IRV
              WV_VeESMC_e_ChrgPwrLimST_ID_A_IRV: accessed-variable=VeESMC_e_ChrgPwrLimST_ID_A_IRV
              WV_VeESMC_e_DschrgPwrLimST_ID_A_IRV: accessed-variable=VeESMC_e_DschrgPwrLimST_ID_A_IRV
              WV_VeESMN_e_EngStartStopSt_IRV: accessed-variable=VeESMN_e_EngStartStopSt_IRV
              WV_VeESMN_e_HVBatCntctrStat_IRV: accessed-variable=VeESMN_e_HVBatCntctrStat_IRV
              WV_VeESMR_P_BatEstdVoltMaxLim_write_IRV: accessed-variable=VeESMR_P_BatEstdVoltMaxLim_write_IRV
              WV_VeESMR_P_BatEstdVoltMinLim_write_IRV: accessed-variable=VeESMR_P_BatEstdVoltMinLim_write_IRV
              WV_VeESMR_P_FCPS_Gen_Pwr_IRV: accessed-variable=VeESMR_P_FCPS_Gen_Pwr_IRV
              WV_VeESMR_P_Total_LT_Chrg_PwrLmtRL_IRV: accessed-variable=VeESMR_P_Total_LT_Chrg_PwrLmtRL_IRV
              WV_VeESMR_P_Total_LT_DsChrg_PwrLmtRL_IRV: accessed-variable=VeESMR_P_Total_LT_DsChrg_PwrLmtRL_IRV
              WV_VeESMR_P_Total_ST_Chrg_PwrLmtRL_IRV: accessed-variable=VeESMR_P_Total_ST_Chrg_PwrLmtRL_IRV, variation-point={short-label=vpWV_VeESMR_P_Total_ST_Chrg_PwrLmtRL_IRV, sw-syscond=1}
              WV_VeESMR_P_Total_ST_DsChrg_PwrLmtRL_IRV: accessed-variable=VeESMR_P_Total_ST_DsChrg_PwrLmtRL_IRV
              WV_VeESMR_U_FCPS_LowerVoltLIM_IRV: accessed-variable=VeESMR_U_FCPS_LowerVoltLIM_IRV
              WV_VeESMR_U_FCPS_UpperVoltLIM_IRV: accessed-variable=VeESMR_U_FCPS_UpperVoltLIM_IRV
              WV_VeESMR_U_FCPS_Volt_IRV: accessed-variable=VeESMR_U_FCPS_Volt_IRV
              WV_VeESMR_b_FCPS_Lower_Voltage_LIM_FA_IRV: accessed-variable=VeESMR_b_FCPS_Lower_Voltage_LIM_FA_IRV
              WV_VeESMR_b_FCPS_Upper_Voltage_LIM_FA_IRV: accessed-variable=VeESMR_b_FCPS_Upper_Voltage_LIM_FA_IRV
              WV_VeESMR_b_FCPS_Volt_FA_IRV: accessed-variable=VeESMR_b_FCPS_Volt_FA_IRV
        ESMR_PwrOff
          data-send-points:
            9 x access:
              OUT_DeESMR_P_HV_BatDschrgPwrLTArb_DeESMR_P_HV_BatDschrgPwrLTArb: accessed-variable=DeESMR_P_HV_BatDschrgPwrLTArb.DeESMR_P_HV_BatDschrgPwrLTArb
              OUT_DeESMR_P_HV_BatChrgPwrLTArb_DeESMR_P_HV_BatChrgPwrLTArb: accessed-variable=DeESMR_P_HV_BatChrgPwrLTArb.DeESMR_P_HV_BatChrgPwrLTArb
              OUT_DeESMR_P_HV_BatChrgPwrSTArb_DeESMR_P_HV_BatChrgPwrSTArb: accessed-variable=DeESMR_P_HV_BatChrgPwrSTArb.DeESMR_P_HV_BatChrgPwrSTArb
              OUT_DeESMR_P_HV_BatDschrgPwrSTArb_DeESMR_P_HV_BatDschrgPwrSTArb: accessed-variable=DeESMR_P_HV_BatDschrgPwrSTArb.DeESMR_P_HV_BatDschrgPwrSTArb
              OUT_DeESMC_I_AccumChrgCurr_DeESMC_I_AccumChrgCurr: accessed-variable=DeESMC_I_AccumChrgCurr.DeESMC_I_AccumChrgCurr
              OUT_DeESMC_I_AccumDisChrgCurr_DeESMC_I_AccumDisChrgCurr: accessed-variable=DeESMC_I_AccumDisChrgCurr.DeESMC_I_AccumDisChrgCurr
              OUT_DeESMC_P_AccumChrgEnergy_DeESMC_P_AccumChrgEnergy: accessed-variable=DeESMC_P_AccumChrgEnergy.DeESMC_P_AccumChrgEnergy
              OUT_DeESMC_P_AccumDisChgEnergy_DeESMC_P_AccumDisChgEnergy: accessed-variable=DeESMC_P_AccumDisChgEnergy.DeESMC_P_AccumDisChgEnergy
              OUT_NeESMC_I_Ahrperhr_DS_NeESMC_I_Ahrperhr_DS: accessed-variable=NeESMC_I_Ahrperhr_DS.NeESMC_I_Ahrperhr_DS
      variation point proxy Variant_ESMR_BoostCnvrtrPwrLmt_Func: category=CONDITION, condition-access=0
      variation point proxy Variant_ESMR_FCPS_Func: category=CONDITION, condition-access=0
      variation point proxy Variant_ESMR_FCPS_NoFunc: category=CONDITION, condition-access=1
